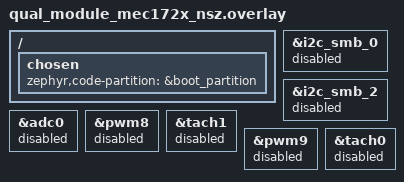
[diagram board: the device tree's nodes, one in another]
/*
 * Copyright (c) 2023 Microchip Technology Inc.
 *
 * SPDX-License-Identifier: Apache-2.0
 */

/ {
    chosen {
        zephyr,code-partition = &boot_partition;
    };
};

// &uart1 {
//     status = "okay";
// 	pinctrl-0 = < &uart1_tx_gpio170 &uart1_rx_gpio171 >;
// 	pinctrl-names = "default";
// };

&i2c_smb_0 {
    status = "disabled";
};

&i2c_smb_2 {
    status = "disabled";
};

&adc0  {
    status = "disabled";
};

&pwm8 {
    status = "disabled";
};

&tach1 {
    status = "disabled";
};

&pwm9 {
    status = "disabled";
};

&tach0 {
    status = "disabled";
};
